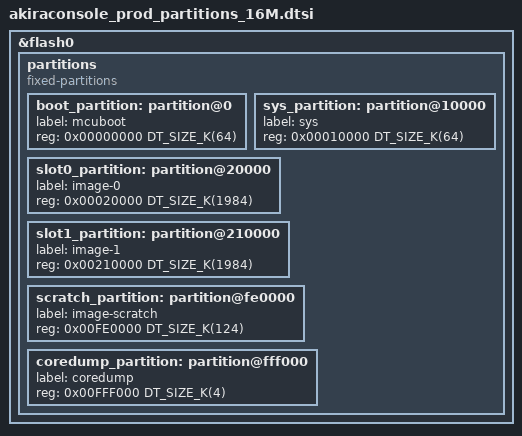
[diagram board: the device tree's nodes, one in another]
/*
 * Copyright (c) 2026 AkiraOS Contributors
 * SPDX-License-Identifier: Apache-2.0
 *
 * AkiraConsole Production (ESP32-S3-WROOM-1-N16R8) partition table.
 *
 * Replaces <espressif/partitions_0x0_amp.dtsi>, whose 4 MB layout caps each
 * MCUboot slot at 1344 KB — less than the firmware needs once BT, WiFi, the
 * RF stack and the USB host stack are all compiled in.
 *
 * The user partitions in akiraconsole_prod_esp32s3_procpu.overlay start at
 * 0x400000 and must not move, so the two image slots divide the space below
 * it exactly:
 *
 *   0x000000  mcuboot         64 KB
 *   0x010000  sys             64 KB   (efuse virt block, see Kconfig.efuse)
 *   0x020000  image-0       1984 KB   slot0 — the running image
 *   0x210000  image-1       1984 KB   slot1 — OTA candidate
 *   0x400000  ...                     user partitions (NVS, LittleFS, hub)
 *   0xFE0000  image-scratch  124 KB   MCUboot revert scratch
 *   0xFFF000  coredump         4 KB
 *
 * The stock table's image-0/1-appcpu and image-0/1-lpcore slots are dropped:
 * core1 runs the same image as core0 here (CONFIG_ESP_APPCPU_AUTOLOAD_IMAGE=n,
 * and esp_appcpu_image_load() is the only consumer), and the S3 has no LP
 * core. Its `storage` partition is dropped too — this board keeps settings and
 * the filesystem in akira_settings_nvs_partition / lfs1_partition instead.
 *
 * Growing the slots past 1984 KB means moving the user partitions, which
 * orphans the NVS and LittleFS content already on shipped devices.
 */

&flash0 {
	partitions {
		compatible = "fixed-partitions";
		#address-cells = <1>;
		#size-cells = <1>;

		boot_partition: partition@0 {
			label = "mcuboot";
			reg = <0x00000000 DT_SIZE_K(64)>;
		};

		sys_partition: partition@10000 {
			label = "sys";
			reg = <0x00010000 DT_SIZE_K(64)>;
		};

		slot0_partition: partition@20000 {
			label = "image-0";
			reg = <0x00020000 DT_SIZE_K(1984)>;
		};

		slot1_partition: partition@210000 {
			label = "image-1";
			reg = <0x00210000 DT_SIZE_K(1984)>;
		};

		scratch_partition: partition@fe0000 {
			label = "image-scratch";
			reg = <0x00FE0000 DT_SIZE_K(124)>;
		};

		coredump_partition: partition@fff000 {
			label = "coredump";
			reg = <0x00FFF000 DT_SIZE_K(4)>;
		};
	};
};
